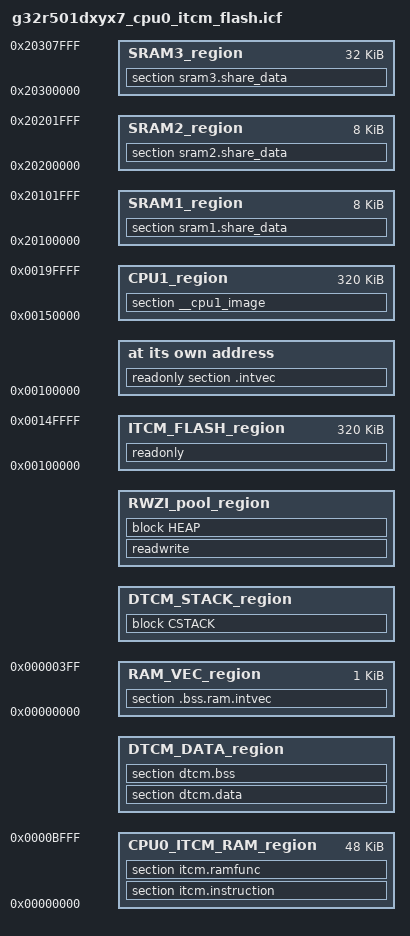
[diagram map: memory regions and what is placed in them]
/*
 * FILE:    g32r501dxyx7_cpu0_itcm_flash.icf
 * TITLE:   IAR linker configuration for G32R501 (dxy CPU0 ITCM Flash)
 * VERSION: 1.0.1
 * DATE:    2026-08-10
 * NOTE:    dxy CPU0 ITCM Flash; VECTOR/RWZI/Boot enabled.
 *          DTCM budget: STACK/HEAP 0x00001000 + 0x400 vector when region=0.
 */

/*###ICF### Section handled by ICF editor, don't touch! ****/
/*-Editor annotation file-*/
/* IcfEditorFile="$TOOLKIT_DIR$\config\linker\Geehy\IcfEditor\g32r501.xml" */
/*-Specials-*/
define symbol __ICFEDIT_intvec_start__ = 0x00100000;
define symbol __ICFEDIT_intvec_size__  = 0x400;
/*0:DTCM, 1:ITCM, 2:None (Lib / no RAM vector)*/
define symbol __vector_region__ = 0;
/*-Memory Regions-*/
define symbol __ICFEDIT_region_CBUS_FLASH_start__    = 0x0;
define symbol __ICFEDIT_region_CBUS_FLASH_end__      = 0x0;
define symbol __ICFEDIT_region_ITCM_FLASH_start__    = 0x00100000;
define symbol __ICFEDIT_region_ITCM_FLASH_end__      = 0x0014FFFF;
define symbol __ICFEDIT_region_CPU0_ITCM_RAM_start__ = 0x00000000;
define symbol __ICFEDIT_region_CPU0_ITCM_RAM_end__   = 0x0000BFFF;
define symbol __ICFEDIT_region_CPU1_ITCM_RAM_start__ = 0x0;
define symbol __ICFEDIT_region_CPU1_ITCM_RAM_end__   = 0x0;
define symbol __ICFEDIT_region_CPU0_DTCM_RAM_start__ = 0x20000000;
define symbol __ICFEDIT_region_CPU0_DTCM_RAM_end__   = 0x20003FFF;
define symbol __ICFEDIT_region_CPU1_DTCM_RAM_start__ = 0x0;
define symbol __ICFEDIT_region_CPU1_DTCM_RAM_end__   = 0x0;
define symbol __ICFEDIT_region_SRAM1_start__         = 0x20100000;
define symbol __ICFEDIT_region_SRAM1_end__           = 0x20101FFF;
define symbol __ICFEDIT_region_SRAM2_start__         = 0x20200000;
define symbol __ICFEDIT_region_SRAM2_end__           = 0x20201FFF;
define symbol __ICFEDIT_region_SRAM3_start__         = 0x20300000;
define symbol __ICFEDIT_region_SRAM3_end__           = 0x20307FFF;

define exported symbol cpu1_image_start     =        0x00150000;
define exported symbol cpu1_image_end       =        0x0019FFFF;

/*-Sizes-*/
define symbol __ICFEDIT_size_cstack__     = 0x3000;
define symbol __ICFEDIT_size_heap__       = 0x0;
/* Set to 1 when G32R501_DTCM_BOOT_STATUS_ENABLE is defined.
 * Reserves last 0x20 bytes of DTCM for Boot status snapshot. */
define symbol __ICFEDIT_boot_status_snapshot_enable__ = 0;
/* bit0 DTCM, bit1 ITCM, bit2 SRAM1, bit3 SRAM2, bit4 SRAM3 */
/* bit0 DTCM, bit1 ITCM, bit2 SRAM1, bit3 SRAM2, bit4 SRAM3 */
/* Align with MDK: exclude ITCM RW/ZI bit (bit1). */
define symbol __ICFEDIT_rwzi_bank__ = 0x0000001D;
/**** End of ICF editor section. ###ICF###*/

/* DTCM budget / stack toward physical top */
define symbol __BOOT_STATUS_SNAPSHOT_size__ = 0x20;
define symbol __DTCM_stack_end__ = __ICFEDIT_region_CPU0_DTCM_RAM_end__ - (__ICFEDIT_boot_status_snapshot_enable__ * __BOOT_STATUS_SNAPSHOT_size__);
define symbol __DTCM_stack_start__ = __DTCM_stack_end__ - __ICFEDIT_size_cstack__ + 1;
define symbol __DTCM_data_end__ = __DTCM_stack_start__ - 1;

define memory mem with size = 4G;
define region CBUS_FLASH_region    = mem:[from __ICFEDIT_region_CBUS_FLASH_start__ to __ICFEDIT_region_CBUS_FLASH_end__];
define region ITCM_FLASH_region    = mem:[from __ICFEDIT_region_ITCM_FLASH_start__ to __ICFEDIT_region_ITCM_FLASH_end__];
define region CPU1_ITCM_RAM_region = mem:[from __ICFEDIT_region_CPU1_ITCM_RAM_start__ to __ICFEDIT_region_CPU1_ITCM_RAM_end__];
define region CPU1_DTCM_RAM_region = mem:[from __ICFEDIT_region_CPU1_DTCM_RAM_start__ to __ICFEDIT_region_CPU1_DTCM_RAM_end__];
define region SRAM1_region         = mem:[from __ICFEDIT_region_SRAM1_start__ to __ICFEDIT_region_SRAM1_end__];
define region SRAM2_region         = mem:[from __ICFEDIT_region_SRAM2_start__ to __ICFEDIT_region_SRAM2_end__];
define region SRAM3_region         = mem:[from __ICFEDIT_region_SRAM3_start__ to __ICFEDIT_region_SRAM3_end__];
define region CPU1_region          = mem:[from cpu1_image_start to cpu1_image_end];

/* REGION=0: RAM vector in DTCM; DTCM_DATA starts after intvec */
if (__vector_region__ == 0)
{
define region CPU0_ITCM_RAM_region = mem:[from __ICFEDIT_region_CPU0_ITCM_RAM_start__ to __ICFEDIT_region_CPU0_ITCM_RAM_end__];
define region DTCM_DATA_region = mem:[from (__ICFEDIT_region_CPU0_DTCM_RAM_start__ + __ICFEDIT_intvec_size__) to __DTCM_data_end__];
define region RAM_VEC_region = mem:[from __ICFEDIT_region_CPU0_DTCM_RAM_start__ to (__ICFEDIT_region_CPU0_DTCM_RAM_start__ + __ICFEDIT_intvec_size__ - 1)];
}
/* REGION=1: RAM vector in ITCM */
else if (__vector_region__ == 1)
{
define region CPU0_ITCM_RAM_region = mem:[from (__ICFEDIT_region_CPU0_ITCM_RAM_start__ + __ICFEDIT_intvec_size__) to __ICFEDIT_region_CPU0_ITCM_RAM_end__];
define region DTCM_DATA_region = mem:[from __ICFEDIT_region_CPU0_DTCM_RAM_start__ to __DTCM_data_end__];
define region RAM_VEC_region = mem:[from __ICFEDIT_region_CPU0_ITCM_RAM_start__ to (__ICFEDIT_region_CPU0_ITCM_RAM_start__ + __ICFEDIT_intvec_size__ - 1)];
}
/* REGION=else: no RAM vector window */
else
{
define region CPU0_ITCM_RAM_region = mem:[from __ICFEDIT_region_CPU0_ITCM_RAM_start__ to __ICFEDIT_region_CPU0_ITCM_RAM_end__];
define region DTCM_DATA_region = mem:[from __ICFEDIT_region_CPU0_DTCM_RAM_start__ to __DTCM_data_end__];
}

define region DTCM_STACK_region  = mem:[from __DTCM_stack_start__ to __DTCM_stack_end__];

define block CSTACK     with alignment = 8, size = __ICFEDIT_size_cstack__     { };
define block HEAP       with alignment = 8, size = __ICFEDIT_size_heap__       { };

if (__vector_region__ <= 1)
{
    do not initialize  { section .noinit, section .bss.ram.intvec };
}
else
{
    do not initialize  { section .noinit };
}

initialize by copy { readwrite,  section dtcm.data, section sram1.share_data,
    section sram2.share_data, section sram3.share_data };
initialize manually { section itcm.instruction, section itcm.ramfunc };

if (isdefinedsymbol(__USE_DLIB_PERTHREAD))
{
  // Required in a multi-threaded application
  initialize by copy with packing = none { section __DLIB_PERTHREAD };
}

place at address mem:__ICFEDIT_intvec_start__ { readonly section .intvec };

place in ITCM_FLASH_region  { readonly };
place in CPU0_ITCM_RAM_region  { section itcm.instruction, section itcm.ramfunc };
place in DTCM_DATA_region   { section dtcm.data, section dtcm.bss };
if ((__ICFEDIT_rwzi_bank__ & 0x1F) == 0) { error "__ICFEDIT_rwzi_bank__ must select at least one bank"; }
/* Keep DTCM for SECTION_DTCM_* only; park generic RW/ZI in SRAM. */
define region RWZI_pool_region = SRAM1_region | SRAM2_region | SRAM3_region;
place in RWZI_pool_region  { readwrite, block HEAP };
place in DTCM_STACK_region  { block CSTACK };
place in SRAM1_region  { section sram1.share_data };
place in SRAM2_region  { section sram2.share_data };
place in SRAM3_region  { section sram3.share_data };
place in CPU1_region   { section __cpu1_image };

if (__vector_region__ <= 1)
{
    /* .bss.ram.intvec -> RAM_VEC_region */
place in RAM_VEC_region { section .bss.ram.intvec };
}
